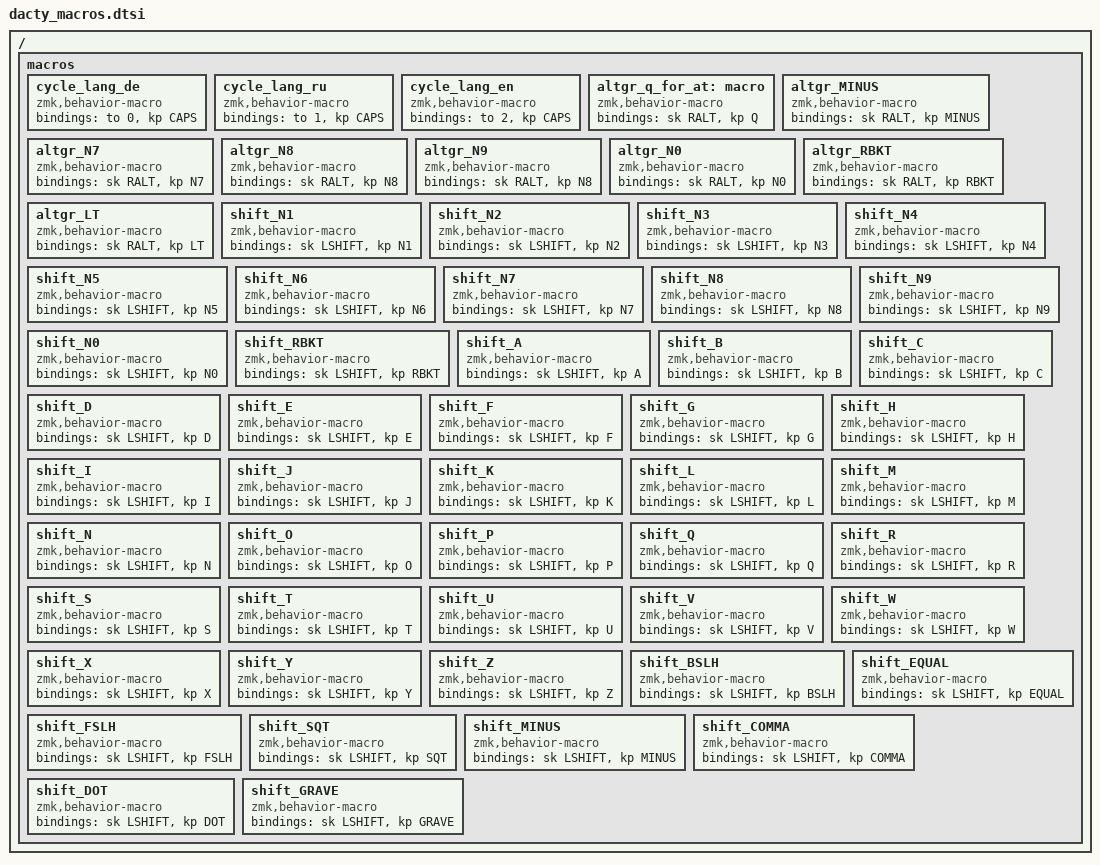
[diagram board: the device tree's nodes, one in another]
/ {

    macros {
        cycle_lang_de: cycle_lang_de {
            compatible = "zmk,behavior-macro";
            #binding-cells = <0>;
            bindings
                = <&to 0>,
                  <&kp CAPS>;
        };

        cycle_lang_ru: cycle_lang_ru {
            compatible = "zmk,behavior-macro";
            #binding-cells = <0>;
            bindings
                = <&to 1>,
                  <&kp CAPS>;
        };

        cycle_lang_en: cycle_lang_en {
            compatible = "zmk,behavior-macro";
            #binding-cells = <0>;
            bindings
                = <&to 2>,
                  <&kp CAPS>;
        };

        altgr_q_for_at: macro {
            compatible = "zmk,behavior-macro";
            #binding-cells = <0>;
            bindings = <&sk RALT &kp Q>;
        };

        altgr_MINUS: altgr_MINUS {
            compatible = "zmk,behavior-macro";
            #binding-cells = <0>;
            bindings = <&sk RALT &kp MINUS>;
        };


        altgr_N7: altgr_N7 {
            compatible = "zmk,behavior-macro";
            #binding-cells = <0>;
            bindings = <&sk RALT &kp N7>;
        };

        altgr_N8: altgr_N8 {
            compatible = "zmk,behavior-macro";
            #binding-cells = <0>;
            bindings = <&sk RALT &kp N8>;
        };

        altgr_N9: altgr_N9 {
            compatible = "zmk,behavior-macro";
            #binding-cells = <0>;
            bindings = <&sk RALT &kp N8>;
        };

        altgr_N0: altgr_N0 {
            compatible = "zmk,behavior-macro";
            #binding-cells = <0>;
            bindings = <&sk RALT &kp N0>;
        };

        altgr_RBKT: altgr_RBKT
        {
            compatible = "zmk,behavior-macro";
            #binding-cells = <0>;
            bindings = <&sk RALT &kp RBKT>;
        };

        altgr_LT: altgr_LT
        {
            compatible = "zmk,behavior-macro";
            #binding-cells = <0>;
            bindings = <&sk RALT &kp LT>;
        };
        

        //======================================

        shift_N1: shift_N1 {
            compatible = "zmk,behavior-macro";
            #binding-cells = <0>;
            bindings = <&sk LSHIFT &kp N1>;
        };

        shift_N2: shift_N2 {
            compatible = "zmk,behavior-macro";
            #binding-cells = <0>;
            bindings = <&sk LSHIFT &kp N2>;
        };

        shift_N3: shift_N3 {
            compatible = "zmk,behavior-macro";
            #binding-cells = <0>;
            bindings = <&sk LSHIFT &kp N3>;
        };

        shift_N4: shift_N4 {
            compatible = "zmk,behavior-macro";
            #binding-cells = <0>;
            bindings = <&sk LSHIFT &kp N4>;
        };

        shift_N5: shift_N5 {
            compatible = "zmk,behavior-macro";
            #binding-cells = <0>;
            bindings = <&sk LSHIFT &kp N5>;
        };

        shift_N6: shift_N6 {
            compatible = "zmk,behavior-macro";
            #binding-cells = <0>;
            bindings = <&sk LSHIFT &kp N6>;
        };

        shift_N7: shift_N7 {
            compatible = "zmk,behavior-macro";
            #binding-cells = <0>;
            bindings = <&sk LSHIFT &kp N7>;
        };

        shift_N8: shift_N8 {
            compatible = "zmk,behavior-macro";
            #binding-cells = <0>;
            bindings = <&sk LSHIFT &kp N8>;
        };

        shift_N9: shift_N9 {
            compatible = "zmk,behavior-macro";
            #binding-cells = <0>;
            bindings = <&sk LSHIFT &kp N9>;
        };

        shift_N0: shift_N0 {
            compatible = "zmk,behavior-macro";
            #binding-cells = <0>;
            bindings = <&sk LSHIFT &kp N0>;
        };

        shift_RBKT: shift_RBKT {
            compatible = "zmk,behavior-macro";
            #binding-cells = <0>;
            bindings = <&sk LSHIFT &kp RBKT>;
        };

        shift_A: shift_A {
            compatible = "zmk,behavior-macro";
            #binding-cells = <0>;
            bindings = <&sk LSHIFT &kp A>;
        };
        shift_B: shift_B {
            compatible = "zmk,behavior-macro";
            #binding-cells = <0>;
            bindings = <&sk LSHIFT &kp B>;
        };
        shift_C: shift_C {
            compatible = "zmk,behavior-macro";
            #binding-cells = <0>;
            bindings = <&sk LSHIFT &kp C>;
        };
        shift_D: shift_D {
            compatible = "zmk,behavior-macro";
            #binding-cells = <0>;
            bindings = <&sk LSHIFT &kp D>;
        };
        shift_E: shift_E {
            compatible = "zmk,behavior-macro";
            #binding-cells = <0>;
            bindings = <&sk LSHIFT &kp E>;
        };
        shift_F: shift_F {
            compatible = "zmk,behavior-macro";
            #binding-cells = <0>;
            bindings = <&sk LSHIFT &kp F>;
        };
        shift_G: shift_G {
            compatible = "zmk,behavior-macro";
            #binding-cells = <0>;
            bindings = <&sk LSHIFT &kp G>;
        };
        shift_H: shift_H {
            compatible = "zmk,behavior-macro";
            #binding-cells = <0>;
            bindings = <&sk LSHIFT &kp H>;
        };
        shift_I: shift_I {
            compatible = "zmk,behavior-macro";
            #binding-cells = <0>;
            bindings = <&sk LSHIFT &kp I>;
        };
        shift_J: shift_J {
            compatible = "zmk,behavior-macro";
            #binding-cells = <0>;
            bindings = <&sk LSHIFT &kp J>;
        };
        shift_K: shift_K {
            compatible = "zmk,behavior-macro";
            #binding-cells = <0>;
            bindings = <&sk LSHIFT &kp K>;
        };
        shift_L: shift_L {
            compatible = "zmk,behavior-macro";
            #binding-cells = <0>;
            bindings = <&sk LSHIFT &kp L>;
        };
        shift_M: shift_M {
            compatible = "zmk,behavior-macro";
            #binding-cells = <0>;
            bindings = <&sk LSHIFT &kp M>;
        };
        shift_N: shift_N {
            compatible = "zmk,behavior-macro";
            #binding-cells = <0>;
            bindings = <&sk LSHIFT &kp N>;
        };
        shift_O: shift_O {
            compatible = "zmk,behavior-macro";
            #binding-cells = <0>;
            bindings = <&sk LSHIFT &kp O>;
        };
        shift_P: shift_P {
            compatible = "zmk,behavior-macro";
            #binding-cells = <0>;
            bindings = <&sk LSHIFT &kp P>;
        };
        shift_Q: shift_Q {
            compatible = "zmk,behavior-macro";
            #binding-cells = <0>;
            bindings = <&sk LSHIFT &kp Q>;
        };
        shift_R: shift_R {
            compatible = "zmk,behavior-macro";
            #binding-cells = <0>;
            bindings = <&sk LSHIFT &kp R>;
        };
        shift_S: shift_S {
            compatible = "zmk,behavior-macro";
            #binding-cells = <0>;
            bindings = <&sk LSHIFT &kp S>;
        };
        shift_T: shift_T {
            compatible = "zmk,behavior-macro";
            #binding-cells = <0>;
            bindings = <&sk LSHIFT &kp T>;
        };
        shift_U: shift_U {
            compatible = "zmk,behavior-macro";
            #binding-cells = <0>;
            bindings = <&sk LSHIFT &kp U>;
        };        
        shift_V: shift_V {
            compatible = "zmk,behavior-macro";
            #binding-cells = <0>;
            bindings = <&sk LSHIFT &kp V>;
        };
        shift_W: shift_W {
            compatible = "zmk,behavior-macro";
            #binding-cells = <0>;
            bindings = <&sk LSHIFT &kp W>;
        };
        shift_X: shift_X {
            compatible = "zmk,behavior-macro";
            #binding-cells = <0>;
            bindings = <&sk LSHIFT &kp X>;
        };
        shift_Y: shift_Y {
            compatible = "zmk,behavior-macro";
            #binding-cells = <0>;
            bindings = <&sk LSHIFT &kp Y>;
        };
        shift_Z: shift_Z {
            compatible = "zmk,behavior-macro";
            #binding-cells = <0>;
            bindings = <&sk LSHIFT &kp Z>;
        };        

        shift_BSLH: shift_BSLH {
            compatible = "zmk,behavior-macro";
            #binding-cells = <0>;
            bindings = <&sk LSHIFT &kp BSLH>;
        };

        shift_EQUAL: shift_EQUAL {
            compatible = "zmk,behavior-macro";
            #binding-cells = <0>;
            bindings = <&sk LSHIFT &kp EQUAL>;
        };

        shift_FSLH: shift_FSLH {
            compatible = "zmk,behavior-macro";
            #binding-cells = <0>;
            bindings = <&sk LSHIFT &kp FSLH>;
        };

        shift_SQT: shift_SQT {
            compatible = "zmk,behavior-macro";
            #binding-cells = <0>;
            bindings = <&sk LSHIFT &kp SQT>;
        };

        shift_MINUS: shift_MINUS {
            compatible = "zmk,behavior-macro";
            #binding-cells = <0>;
            bindings = <&sk LSHIFT &kp MINUS>;
        };

        shift_COMMA: shift_COMMA {
            compatible = "zmk,behavior-macro";
            #binding-cells = <0>;
            bindings = <&sk LSHIFT &kp COMMA>;
        };

        shift_DOT: shift_DOT {
            compatible = "zmk,behavior-macro";
            #binding-cells = <0>;
            bindings = <&sk LSHIFT &kp DOT>;
        };

        shift_GRAVE: shift_GRAVE {
            compatible = "zmk,behavior-macro";
            #binding-cells = <0>;
            bindings = <&sk LSHIFT &kp GRAVE>;
        };

        


    };

};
